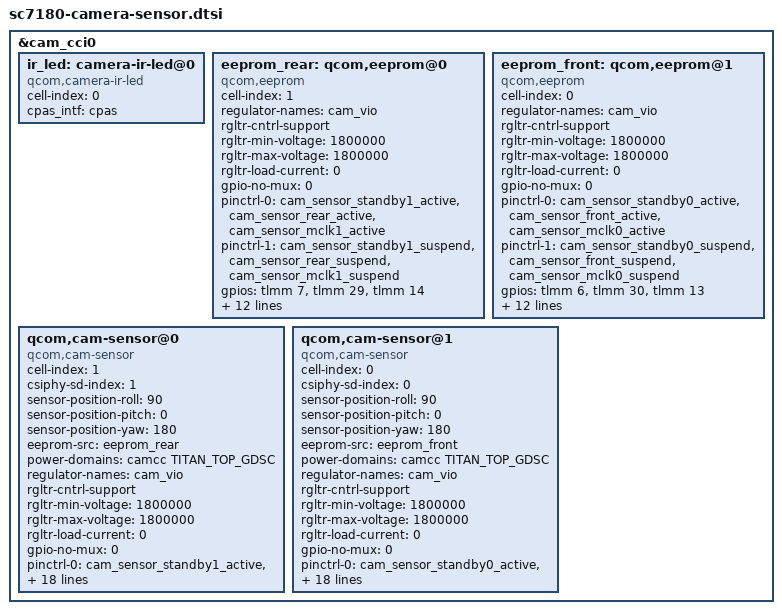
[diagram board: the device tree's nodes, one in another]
// SPDX-License-Identifier: BSD-3-Clause
/*
 * Copyright (c) 2019, The Linux Foundation. All rights reserved.
 *
 * This program is free software; you can redistribute it and/or modify
 * it under the terms of the GNU General Public License version 2 and
 * only version 2 as published by the Free Software Foundation.
 *
 * This program is distributed in the hope that it will be useful,
 * but WITHOUT ANY WARRANTY; without even the implied warranty of
 * MERCHANTABILITY or FITNESS FOR A PARTICULAR PURPOSE.  See the
 * GNU General Public License for more details.
 */

#include "sc7180-camera-cci.dtsi"

&cam_cci0 {

	ir_led: camera-ir-led@0 {
		cell-index = <0>;
		cpas_intf = <&cpas>;
		compatible = "qcom,camera-ir-led";
	};

	eeprom_rear: qcom,eeprom@0 {
		cell-index = <1>;
		compatible = "qcom,eeprom";
		regulator-names = "cam_vio";
		rgltr-cntrl-support;
		rgltr-min-voltage = <1800000>;
		rgltr-max-voltage = <1800000>;
		rgltr-load-current = <0>;
		gpio-no-mux = <0>;
		pinctrl-names = "cam_default", "cam_suspend";
		pinctrl-0 = <&cam_sensor_standby1_active
			&cam_sensor_rear_active
			&cam_sensor_mclk1_active>;
		pinctrl-1 = <&cam_sensor_standby1_suspend
			&cam_sensor_rear_suspend
			&cam_sensor_mclk1_suspend>;
		gpios = <&tlmm 7 0>,
			<&tlmm 29 0>,
			<&tlmm 14 0>;
		gpio-standby = <0>;
		gpio-reset = <1>;
		gpio-req-tbl-num = <0 1 2>;
		gpio-req-tbl-flags = <0 0 1>;
		gpio-req-tbl-label = "CAM_STANDBY1",
					"CAM_RESET1",
					"CAMIF_MCLK1";
		sensor-mode = <0>;
		cci-device = <0>;
		cci-master = <1>;
		status = "ok";
		clocks = <&camcc CAM_CC_MCLK1_CLK>;
		clock-names = "cam_clk";
		clock-cntl-level = "turbo";
		clock-rates = <24000000>;
	};

	eeprom_front: qcom,eeprom@1 {
		cell-index = <0>;
		compatible = "qcom,eeprom";
		regulator-names = "cam_vio";
		rgltr-cntrl-support;
		rgltr-min-voltage = <1800000>;
		rgltr-max-voltage = <1800000>;
		rgltr-load-current = <0>;
		gpio-no-mux = <0>;
		pinctrl-names = "cam_default", "cam_suspend";
		pinctrl-0 = <&cam_sensor_standby0_active
			&cam_sensor_front_active
			&cam_sensor_mclk0_active>;
		pinctrl-1 = <&cam_sensor_standby0_suspend
			&cam_sensor_front_suspend
			&cam_sensor_mclk0_suspend>;
		gpios = <&tlmm 6 0>,
			<&tlmm 30 0>,
			<&tlmm 13 0>;
		gpio-standby = <0>;
		gpio-reset = <1>;
		gpio-req-tbl-num = <0 1 2>;
		gpio-req-tbl-flags = <0 0 1>;
		gpio-req-tbl-label = "CAM_STANDBY0",
					"CAM_RESET0",
					"CAMIF_MCLK0";
		sensor-mode = <0>;
		cci-device = <0>;
		cci-master = <0>;
		status = "ok";
		clocks = <&camcc CAM_CC_MCLK0_CLK>;
		clock-names = "cam_clk";
		clock-cntl-level = "turbo";
		clock-rates = <24000000>;
	};

	qcom,cam-sensor@0 {
		cell-index = <1>;
		compatible = "qcom,cam-sensor";
		csiphy-sd-index = <1>;
		sensor-position-roll = <90>;
		sensor-position-pitch = <0>;
		sensor-position-yaw = <180>;
		eeprom-src = <&eeprom_rear>;
		power-domains = <&camcc TITAN_TOP_GDSC>;
		regulator-names = "cam_vio";
		rgltr-cntrl-support;
		rgltr-min-voltage = <1800000>;
		rgltr-max-voltage = <1800000>;
		rgltr-load-current = <0>;
		gpio-no-mux = <0>;
		pinctrl-names = "cam_default", "cam_suspend";
		pinctrl-0 = <&cam_sensor_standby1_active
			&cam_sensor_rear_active
			&cam_sensor_mclk1_active>;
		pinctrl-1 = <&cam_sensor_standby1_suspend
			&cam_sensor_rear_suspend
			&cam_sensor_mclk1_suspend>;
		gpios = <&tlmm 7 0>,
			<&tlmm 29 0>,
			<&tlmm 14 0>;
		gpio-standby = <0>;
		gpio-reset = <1>;
		gpio-req-tbl-num = <0 1 2>;
		gpio-req-tbl-flags = <0 0 1>;
		gpio-req-tbl-label = "CAM_STANDBY1",
					"CAM_RESET1",
					"CAMIF_MCLK1";
		sensor-mode = <0>;
		cci-device = <0>;
		cci-master = <1>;
		clocks = <&camcc CAM_CC_MCLK1_CLK>;
		clock-names = "cam_clk";
		clock-cntl-level = "turbo";
		clock-rates = <24000000>;
	};

	qcom,cam-sensor@1 {
		cell-index = <0>;
		compatible = "qcom,cam-sensor";
		csiphy-sd-index = <0>;
		sensor-position-roll = <90>;
		sensor-position-pitch = <0>;
		sensor-position-yaw = <180>;
		eeprom-src = <&eeprom_front>;
		power-domains = <&camcc TITAN_TOP_GDSC>;
		regulator-names = "cam_vio";
		rgltr-cntrl-support;
		rgltr-min-voltage = <1800000>;
		rgltr-max-voltage = <1800000>;
		rgltr-load-current = <0>;
		gpio-no-mux = <0>;
		pinctrl-names = "cam_default", "cam_suspend";
		pinctrl-0 = <&cam_sensor_standby0_active
			&cam_sensor_front_active
			&cam_sensor_mclk0_active>;
		pinctrl-1 = <&cam_sensor_standby0_suspend
			&cam_sensor_front_suspend
			&cam_sensor_mclk0_suspend>;
		gpios = <&tlmm 6 0>,
			<&tlmm 30 0>,
			<&tlmm 13 0>;
		gpio-standby = <0>;
		gpio-reset = <1>;
		gpio-req-tbl-num = <0 1 2>;
		gpio-req-tbl-flags = <0 0 1>;
		gpio-req-tbl-label = "CAM_STANDBY0",
					"CAM_RESET0",
					"CAMIF_MCLK0";
		sensor-mode = <0>;
		cci-device = <0>;
		cci-master = <0>;
		clocks = <&camcc CAM_CC_MCLK0_CLK>;
		clock-names = "cam_clk";
		clock-cntl-level = "turbo";
		clock-rates = <24000000>;
	};
};
